# ESP32-S31 register map
Vendor: ESPRESSIF SYSTEMS (SHANGHAI) CO., LTD.; Series: ESP32 S-Series; File version: 1
CPU: RV32IMAFC r0p0, little endian, no MPU, FPU, 0 interrupt priority bits
Address unit: 32 bits
Registers are 32-bit, read-write, reset 0x0 unless marked. A register's access mark holds for its fields unless they carry their own. Offsets are from the block's base; [hi:lo] are bit positions; {n}, {i} and the like mark numbered series; 'fields as' and 'values as' point back to an identical list.

## MEMSPI3 — Memory SPI 3
Base 0x20503000
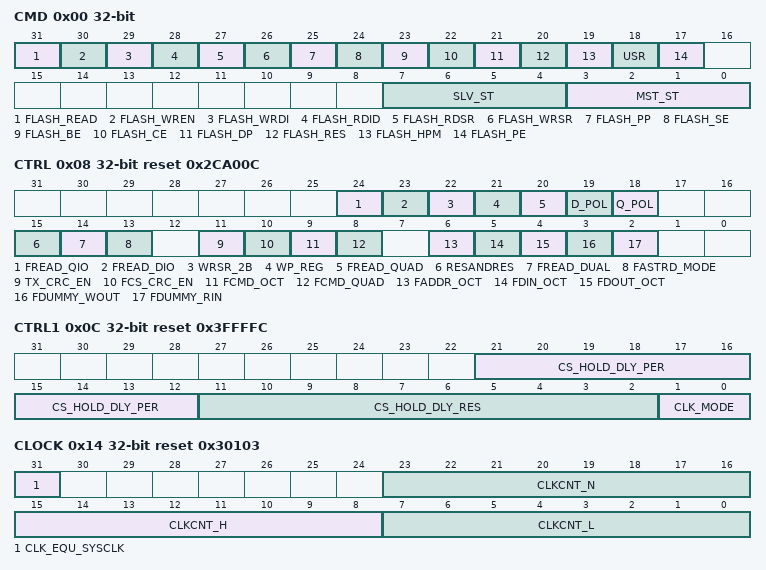
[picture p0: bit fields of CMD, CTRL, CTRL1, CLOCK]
0x00 CMD access per field — SPI1 memory command register
  [31] FLASH_READ rw, [30] FLASH_WREN rw, [29] FLASH_WRDI rw, [28] FLASH_RDID rw, [27] FLASH_RDSR rw, [26] FLASH_WRSR rw, [25] FLASH_PP rw, [24] FLASH_SE rw, [23] FLASH_BE rw, [22] FLASH_CE rw, [21] FLASH_DP rw, [20] FLASH_RES rw, [19] FLASH_HPM rw, [18] USR rw, [17] FLASH_PE rw, [7:4] SLV_ST ro, [3:0] MST_ST ro
0x04 ADDR — SPI1 address register
  [31:0] USR_ADDR_VALUE
0x08 CTRL reset 0x2CA00C — SPI1 control register.
  [24] FREAD_QIO, [23] FREAD_DIO, [22] WRSR_2B, [21] WP_REG, [20] FREAD_QUAD, [19] D_POL, [18] Q_POL, [15] RESANDRES, [14] FREAD_DUAL, [13] FASTRD_MODE, [11] TX_CRC_EN, [10] FCS_CRC_EN, [9] FCMD_OCT, [8] FCMD_QUAD, [6] FADDR_OCT, [5] FDIN_OCT, [4] FDOUT_OCT, [3] FDUMMY_WOUT, [2] FDUMMY_RIN
0x0C CTRL1 reset 0x3FFFFC — SPI1 control1 register.
  [21:12] CS_HOLD_DLY_PER, [11:2] CS_HOLD_DLY_RES, [1:0] CLK_MODE
0x10 CTRL2 wo — SPI1 control2 register.
  [31] SYNC_RESET
0x14 CLOCK reset 0x30103 — SPI1 clock division control register.
  [31] CLK_EQU_SYSCLK, [23:16] CLKCNT_N, [15:8] CLKCNT_H, [7:0] CLKCNT_L
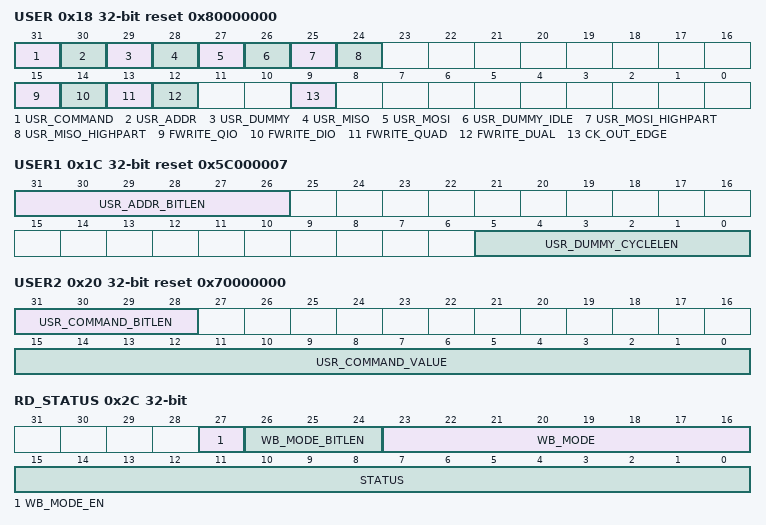
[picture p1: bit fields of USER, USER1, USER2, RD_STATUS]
0x18 USER reset 0x80000000 — SPI1 user register.
  [31] USR_COMMAND, [30] USR_ADDR, [29] USR_DUMMY, [28] USR_MISO, [27] USR_MOSI, [26] USR_DUMMY_IDLE, [25] USR_MOSI_HIGHPART, [24] USR_MISO_HIGHPART, [15] FWRITE_QIO, [14] FWRITE_DIO, [13] FWRITE_QUAD, [12] FWRITE_DUAL, [9] CK_OUT_EDGE
0x1C USER1 reset 0x5C000007 — SPI1 user1 register.
  [31:26] USR_ADDR_BITLEN, [5:0] USR_DUMMY_CYCLELEN
0x20 USER2 reset 0x70000000 — SPI1 user2 register.
  [31:28] USR_COMMAND_BITLEN, [15:0] USR_COMMAND_VALUE
0x24 MOSI_DLEN — SPI1 send data bit length control register.
  [9:0] USR_MOSI_DBITLEN
0x28 MISO_DLEN — SPI1 receive data bit length control register.
  [9:0] USR_MISO_DBITLEN
0x2C RD_STATUS — SPI1 status register.
  [27] WB_MODE_EN, [26:24] WB_MODE_BITLEN, [23:16] WB_MODE, [15:0] STATUS
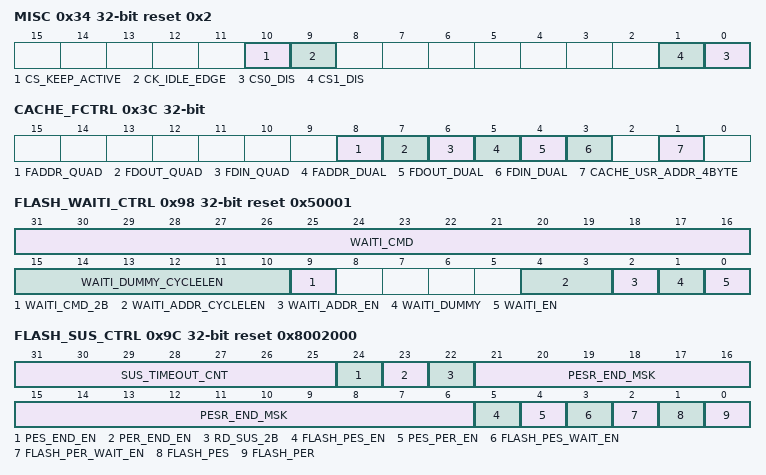
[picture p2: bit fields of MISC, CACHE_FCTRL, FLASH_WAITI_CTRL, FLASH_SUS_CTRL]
0x34 MISC reset 0x2 — SPI1 misc register
  [10] CS_KEEP_ACTIVE, [9] CK_IDLE_EDGE, [n] CS{n}_DIS (n=0..1)
0x38 TX_CRC ro reset 0xFFFFFFFF — SPI1 TX CRC data register.
  [31:0] DATA
0x3C CACHE_FCTRL — SPI1 bit mode control register.
  [8] FADDR_QUAD, [7] FDOUT_QUAD, [6] FDIN_QUAD, [5] FADDR_DUAL, [4] FDOUT_DUAL, [3] FDIN_DUAL, [1] CACHE_USR_ADDR_4BYTE
{0x58+4i} W{i} (i=0..15) — SPI1 memory data buffer0
  [31:0] BUF
0x98 FLASH_WAITI_CTRL reset 0x50001 — SPI1 wait idle control register
  [31:16] WAITI_CMD, [15:10] WAITI_DUMMY_CYCLELEN, [9] WAITI_CMD_2B, [4:3] WAITI_ADDR_CYCLELEN, [2] WAITI_ADDR_EN, [1] WAITI_DUMMY, [0] WAITI_EN
0x9C FLASH_SUS_CTRL reset 0x8002000 — SPI1 flash suspend control register
  [31:25] SUS_TIMEOUT_CNT, [24] PES_END_EN, [23] PER_END_EN, [22] RD_SUS_2B, [21:6] PESR_END_MSK, [5] FLASH_PES_EN, [4] PES_PER_EN, [3] FLASH_PES_WAIT_EN, [2] FLASH_PER_WAIT_EN, [1] FLASH_PES, [0] FLASH_PER
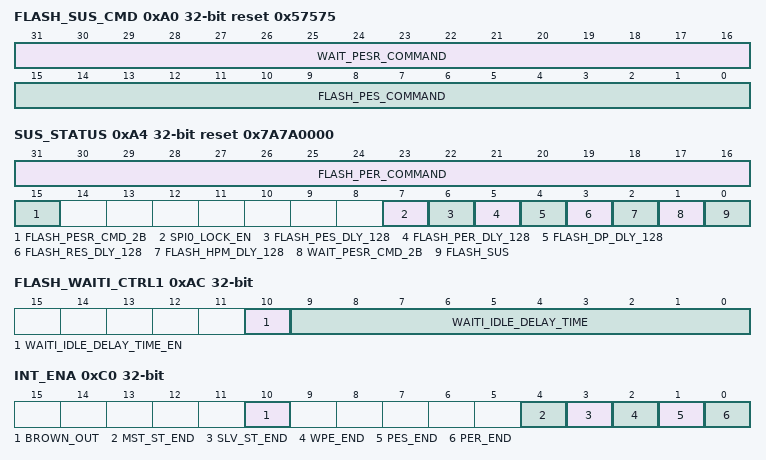
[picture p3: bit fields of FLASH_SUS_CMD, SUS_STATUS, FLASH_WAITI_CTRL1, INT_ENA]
0xA0 FLASH_SUS_CMD reset 0x57575 — SPI1 flash suspend command register
  [31:16] WAIT_PESR_COMMAND, [15:0] FLASH_PES_COMMAND
0xA4 SUS_STATUS reset 0x7A7A0000 — SPI1 flash suspend status register
  [31:16] FLASH_PER_COMMAND, [15] FLASH_PESR_CMD_2B, [7] SPI0_LOCK_EN, [6] FLASH_PES_DLY_128, [5] FLASH_PER_DLY_128, [4] FLASH_DP_DLY_128, [3] FLASH_RES_DLY_128, [2] FLASH_HPM_DLY_128, [1] WAIT_PESR_CMD_2B, [0] FLASH_SUS
0xAC FLASH_WAITI_CTRL1 — SPI1 wait idle control register
  [10] WAITI_IDLE_DELAY_TIME_EN, [9:0] WAITI_IDLE_DELAY_TIME
0xC0 INT_ENA — SPI1 interrupt enable register
  [10] BROWN_OUT, [4] MST_ST_END, [3] SLV_ST_END, [2] WPE_END, [1] PES_END, [0] PER_END
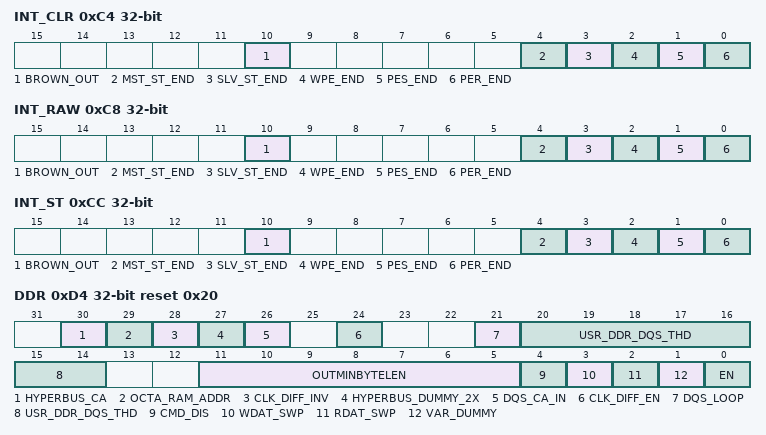
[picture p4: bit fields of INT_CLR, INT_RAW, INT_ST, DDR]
0xC4 INT_CLR wo — SPI1 interrupt clear register
  [10] BROWN_OUT write-1-clears, [4] MST_ST_END write-1-clears, [3] SLV_ST_END write-1-clears, [2] WPE_END write-1-clears, [1] PES_END write-1-clears, [0] PER_END write-1-clears
0xC8 INT_RAW — SPI1 interrupt raw register
  fields as INT_ENA
0xCC INT_ST ro — SPI1 interrupt status register
  fields as INT_ENA
0xD4 DDR reset 0x20 — SPI1 DDR control register
  [30] HYPERBUS_CA, [29] OCTA_RAM_ADDR, [28] CLK_DIFF_INV, [27] HYPERBUS_DUMMY_2X, [26] DQS_CA_IN, [24] CLK_DIFF_EN, [21] DQS_LOOP, [20:14] USR_DDR_DQS_THD, [11:5] OUTMINBYTELEN, [4] CMD_DIS, [3] WDAT_SWP, [2] RDAT_SWP, [1] VAR_DUMMY, [0] EN
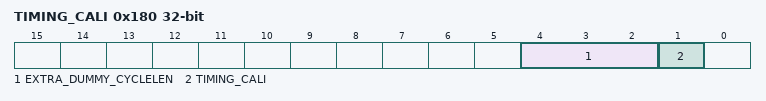
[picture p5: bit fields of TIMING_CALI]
0x180 TIMING_CALI — SPI1 timing control register
  [4:2] EXTRA_DUMMY_CYCLELEN, [1] TIMING_CALI
0x200 CLOCK_GATE reset 0x1 — SPI1 clk_gate register
  [0] CLK_EN
0x3FC DATE reset 0x2409240 — Version control register
  [27:0] DATE
